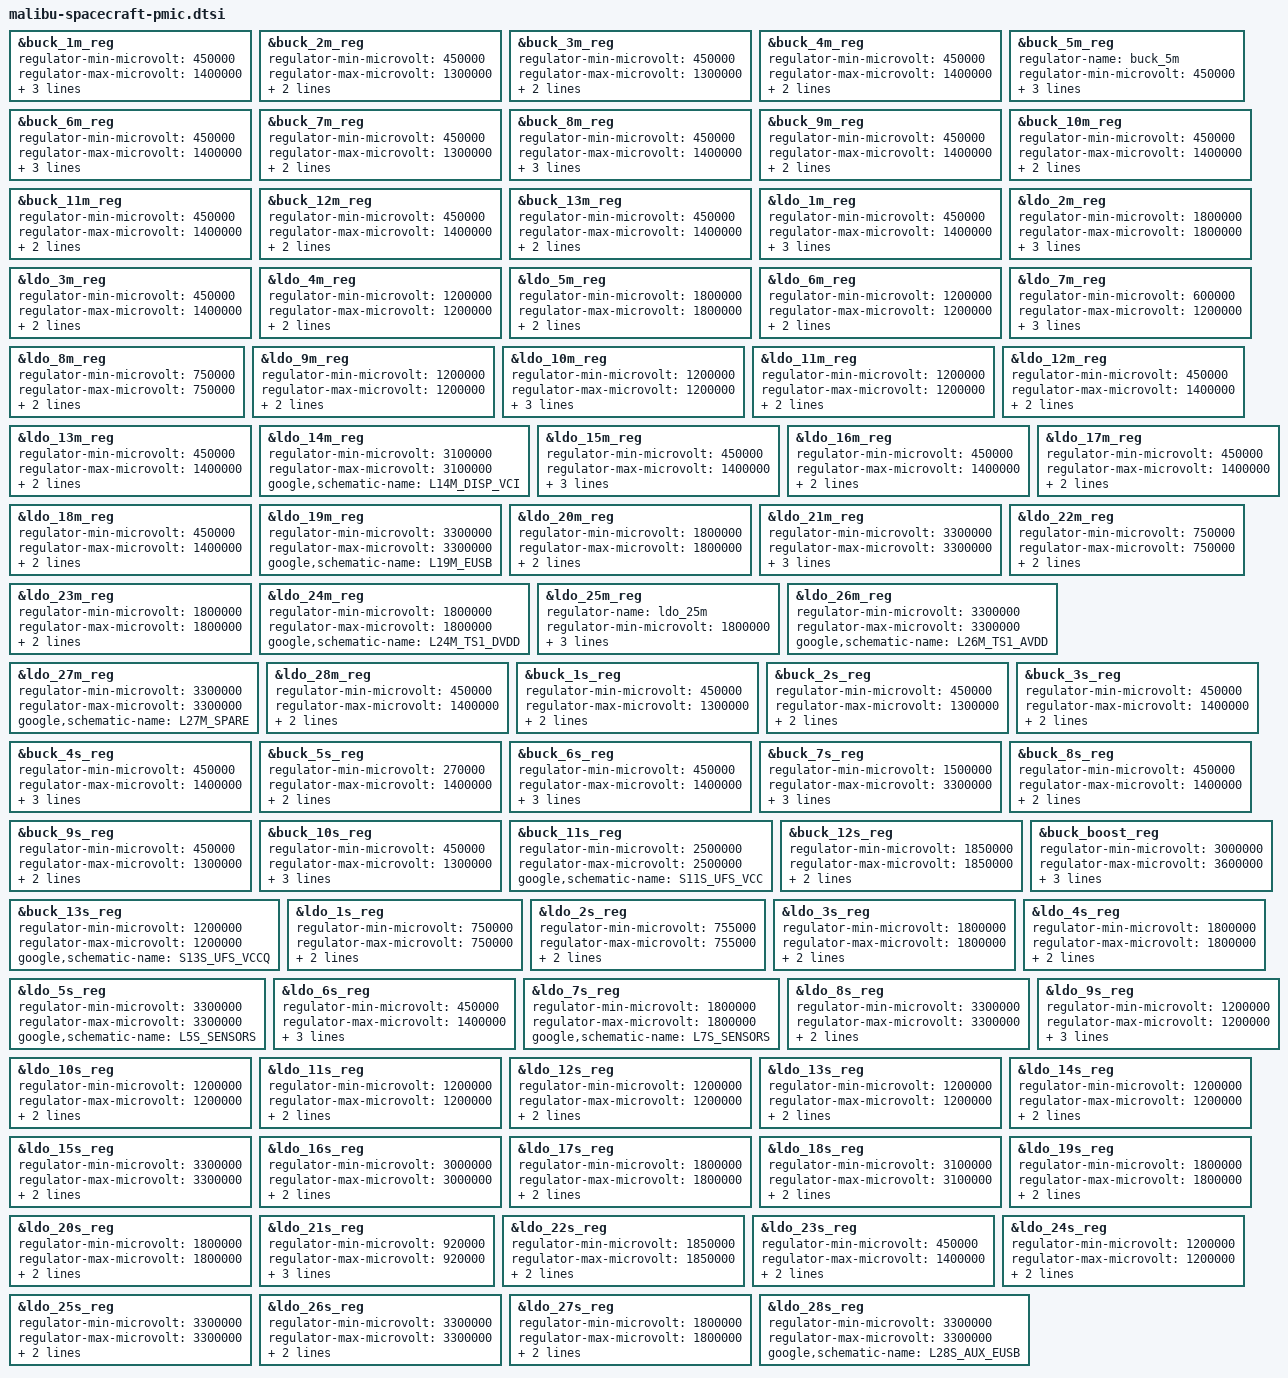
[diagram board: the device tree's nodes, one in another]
// SPDX-License-Identifier: GPL-2.0-only
/*
 * Spacecraft power regulator adjusment device tree source
 *
 * Copyright 2025 Google LLC
 */

&buck_1m_reg {
	regulator-min-microvolt = <450000>;
	regulator-max-microvolt = <1400000>;
	google,schematic-name = "S1M_VDD_AMB";
	google,subsystem-name = "AMB";
	google,monitor-only;
};

&buck_2m_reg {
	regulator-min-microvolt = <450000>;
	regulator-max-microvolt = <1300000>;
	google,schematic-name = "S2M_VDD_CPU2";
	google,monitor-only;
};

&buck_3m_reg {
	regulator-min-microvolt = <450000>;
	regulator-max-microvolt = <1300000>;
	google,schematic-name = "S3M_VDD_CPU1";
	google,monitor-only;
};

&buck_4m_reg {
	regulator-min-microvolt = <450000>;
	regulator-max-microvolt = <1400000>;
	google,schematic-name = "S4M_VDD_AUR";
	google,monitor-only;
};

&buck_5m_reg {
	regulator-name = "buck_5m";
	regulator-min-microvolt = <450000>;
	regulator-max-microvolt = <1300000>;
	google,schematic-name = "S5M_VDD_DSU";
	google,monitor-only;
};

&buck_6m_reg {
	regulator-min-microvolt = <450000>;
	regulator-max-microvolt = <1400000>;
	google,schematic-name = "S6M_LLDO1";
	google,monitor-only;
	regulator-always-on;
};

&buck_7m_reg {
	regulator-min-microvolt = <450000>;
	regulator-max-microvolt = <1300000>;
	google,schematic-name = "S7M_VDD_TPU";
	google,monitor-only;
};

&buck_8m_reg {
	regulator-min-microvolt = <450000>;
	regulator-max-microvolt = <1400000>;
	google,schematic-name = "S8M_LLDO2";
	google,monitor-only;
	regulator-always-on;
};

&buck_9m_reg {
	regulator-min-microvolt = <450000>;
	regulator-max-microvolt = <1400000>;
	google,schematic-name = "S9M_VDD_AOSS";
	google,monitor-only;
};

&buck_10m_reg {
	regulator-min-microvolt = <450000>;
	regulator-max-microvolt = <1400000>;
	google,schematic-name = "S10M_VDD_AOSS_OD";
	google,monitor-only;
};

&buck_11m_reg {
	regulator-min-microvolt = <450000>;
	regulator-max-microvolt = <1400000>;
	google,schematic-name = "S11M_VDD_DSU_M";
	google,monitor-only;
};

&buck_12m_reg {
	regulator-min-microvolt = <450000>;
	regulator-max-microvolt = <1400000>;
	google,schematic-name = "S12M_VDD_CPU1_M";
	google,monitor-only;
};

&buck_13m_reg {
	regulator-min-microvolt = <450000>;
	regulator-max-microvolt = <1400000>;
	google,schematic-name = "S13M_VDD_CPU0";
	google,monitor-only;
};

&ldo_1m_reg {
	regulator-min-microvolt = <450000>;
	regulator-max-microvolt = <1400000>;
	google,schematic-name = "L1M_ALIVE";
	google,monitor-only;
	regulator-always-on;
};

&ldo_2m_reg {
	regulator-min-microvolt = <1800000>;
	regulator-max-microvolt = <1800000>;
	google,schematic-name = "L2M_ALIVE";
	google,monitor-only;
	regulator-always-on;
};

&ldo_3m_reg {
	regulator-min-microvolt = <450000>;
	regulator-max-microvolt = <1400000>;
	google,schematic-name = "L3M_SPARE";
	google,monitor-only;
};

&ldo_4m_reg {
	regulator-min-microvolt = <1200000>;
	regulator-max-microvolt = <1200000>;
	google,schematic-name = "L4M_BT_AON";
	google,monitor-only;
};

&ldo_5m_reg {
	regulator-min-microvolt = <1800000>;
	regulator-max-microvolt = <1800000>;
	google,schematic-name = "L5M_S5910_AON";
	google,monitor-only;
};

&ldo_6m_reg {
	regulator-min-microvolt = <1200000>;
	regulator-max-microvolt = <1200000>;
	google,schematic-name = "L6M_HSI";
	google,monitor-only;
};

&ldo_7m_reg {
	/* Note:ldo_7m is current sink, not design to output voltage */
	regulator-min-microvolt = <600000>;
	regulator-max-microvolt = <1200000>;
	google,schematic-name = "L7M_SOC_GPIO";
	google,monitor-only;
	regulator-always-on;
};

&ldo_8m_reg {
	regulator-min-microvolt = <750000>;
	regulator-max-microvolt = <750000>;
	google,schematic-name = "L8M_SPARE";
	google,monitor-only;
};

&ldo_9m_reg {
	regulator-min-microvolt = <1200000>;
	regulator-max-microvolt = <1200000>;
	google,schematic-name = "L9M_SPARE";
	google,monitor-only;
};

&ldo_10m_reg {
	regulator-min-microvolt = <1200000>;
	regulator-max-microvolt = <1200000>;
	google,schematic-name = "L10M_SOC_GPIO";
	google,monitor-only;
	regulator-always-on;
};

&ldo_11m_reg {
	regulator-min-microvolt = <1200000>;
	regulator-max-microvolt = <1200000>;
	google,schematic-name = "L11M_VDD_CPU0_M";
	google,monitor-only;
};

&ldo_12m_reg {
	regulator-min-microvolt = <450000>;
	regulator-max-microvolt = <1400000>;
	google,schematic-name = "L12M_VDD_CPU2_M";
	google,monitor-only;
};

&ldo_13m_reg {
	regulator-min-microvolt = <450000>;
	regulator-max-microvolt = <1400000>;
	google,schematic-name = "L13M_VDD_TPU_M";
	google,monitor-only;
};

&ldo_14m_reg {
	regulator-min-microvolt = <3100000>;
	regulator-max-microvolt = <3100000>;
	google,schematic-name = "L14M_DISP_VCI";
};

&ldo_15m_reg {
	regulator-min-microvolt = <450000>;
	regulator-max-microvolt = <1400000>;
	google,schematic-name = "L15M_USB_PCIE";
	google,monitor-only;
	regulator-always-on;
};

&ldo_16m_reg {
	regulator-min-microvolt = <450000>;
	regulator-max-microvolt = <1400000>;
	google,schematic-name = "L16M_VDD_AMB_M";
	google,monitor-only;
};

&ldo_17m_reg {
	regulator-min-microvolt = <450000>;
	regulator-max-microvolt = <1400000>;
	google,schematic-name = "L17M_VDD_TPU_SSWRP";
	google,monitor-only;
};

&ldo_18m_reg {
	regulator-min-microvolt = <450000>;
	regulator-max-microvolt = <1400000>;
	google,schematic-name = "L18M_SPARE";
	google,monitor-only;
};

&ldo_19m_reg {
	regulator-min-microvolt = <3300000>;
	regulator-max-microvolt = <3300000>;
	google,schematic-name = "L19M_EUSB";
};

&ldo_20m_reg {
	regulator-min-microvolt = <1800000>;
	regulator-max-microvolt = <1800000>;
	google,schematic-name = "L20M_DMIC1";
	google,monitor-only;
};

&ldo_21m_reg {
	regulator-min-microvolt = <3300000>;
	regulator-max-microvolt = <3300000>;
	google,schematic-name = "L21M_GSC";
	google,monitor-only;
	regulator-always-on;
};

&ldo_22m_reg {
	regulator-min-microvolt = <750000>;
	regulator-max-microvolt = <750000>;
	google,schematic-name = "L22M_SPARE";
	google,monitor-only;
};

&ldo_23m_reg {
	regulator-min-microvolt = <1800000>;
	regulator-max-microvolt = <1800000>;
	google,schematic-name = "L23M_SPARE";
	google,monitor-only;
};

&ldo_24m_reg {
	regulator-min-microvolt = <1800000>;
	regulator-max-microvolt = <1800000>;
	google,schematic-name = "L24M_TS1_DVDD";
};

&ldo_25m_reg {
	regulator-name = "ldo_25m";
	regulator-min-microvolt = <1800000>;
	regulator-max-microvolt = <1800000>;
	google,schematic-name = "L25M_AVDD_OTP";
	google,monitor-only;
};

&ldo_26m_reg {
	regulator-min-microvolt = <3300000>;
	regulator-max-microvolt = <3300000>;
	google,schematic-name = "L26M_TS1_AVDD";
};

&ldo_27m_reg {
	regulator-min-microvolt = <3300000>;
	regulator-max-microvolt = <3300000>;
	google,schematic-name = "L27M_SPARE";
};

&ldo_28m_reg {
	regulator-min-microvolt = <450000>;
	regulator-max-microvolt = <1400000>;
	google,schematic-name = "L28M_VDD_HSION";
	google,monitor-only;
};

&buck_1s_reg {
	regulator-min-microvolt = <450000>;
	regulator-max-microvolt = <1300000>;
	google,schematic-name = "S1S_VDD_MM";
	google,monitor-only;
};

&buck_2s_reg {
	regulator-min-microvolt = <450000>;
	regulator-max-microvolt = <1300000>;
	google,schematic-name = "S2S_VDD_GPU";
	google,monitor-only;
};

&buck_3s_reg {
	regulator-min-microvolt = <450000>;
	regulator-max-microvolt = <1400000>;
	google,schematic-name = "S3S_LLDO1";
	google,monitor-only;
};

&buck_4s_reg {
	regulator-min-microvolt = <450000>;
	regulator-max-microvolt = <1400000>;
	google,schematic-name = "S4S_VDD2H_MEM";
	google,monitor-only;
	regulator-always-on;
};

&buck_5s_reg {
	regulator-min-microvolt = <270000>;
	regulator-max-microvolt = <1400000>;
	google,schematic-name = "S5S_VDDQ_MEM";
	google,monitor-only;
};

&buck_6s_reg {
	regulator-min-microvolt = <450000>;
	regulator-max-microvolt = <1400000>;
	google,schematic-name = "S6S_LLDO2";
	google,monitor-only;
	regulator-always-on;
};

&buck_7s_reg {
	regulator-min-microvolt = <1500000>;
	regulator-max-microvolt = <3300000>;
	google,schematic-name = "S7S_MLDO";
	google,monitor-only;
	regulator-always-on;
};

&buck_8s_reg {
	regulator-min-microvolt = <450000>;
	regulator-max-microvolt = <1400000>;
	google,schematic-name = "S8S_VDD_GMC";
	google,monitor-only;
};

&buck_9s_reg {
	regulator-min-microvolt = <450000>;
	regulator-max-microvolt = <1300000>;
	google,schematic-name = "S9S_VDD_INFRA";
	google,monitor-only;
};

&buck_10s_reg {
	regulator-min-microvolt = <450000>;
	regulator-max-microvolt = <1300000>;
	google,schematic-name = "S10S_VDD_INFRA_MM_GPU_AUR_M";
	google,monitor-only;
};

&buck_11s_reg {
	regulator-min-microvolt = <2500000>;
	regulator-max-microvolt = <2500000>;
	google,schematic-name = "S11S_UFS_VCC";
};

&buck_12s_reg {
	regulator-min-microvolt = <1850000>;
	regulator-max-microvolt = <1850000>;
	google,schematic-name = "S12S";
	regulator-always-on;
};

&buck_13s_reg {
	regulator-min-microvolt = <1200000>;
	regulator-max-microvolt = <1200000>;
	google,schematic-name = "S13S_UFS_VCCQ";
};

&buck_boost_reg {
	regulator-min-microvolt = <3000000>;
	regulator-max-microvolt = <3600000>;
	google,schematic-name = "BB_HLDO";
	google,monitor-only;
	regulator-always-on;
};

&ldo_1s_reg {
	regulator-min-microvolt = <750000>;
	regulator-max-microvolt = <750000>;
	google,schematic-name = "L1S_PLL_HSIO";
	regulator-always-on;
};

&ldo_2s_reg {
	regulator-min-microvolt = <755000>;
	regulator-max-microvolt = <755000>;
	google,schematic-name = "L2S_CSI";
	google,monitor-only;
};

&ldo_3s_reg {
	regulator-min-microvolt = <1800000>;
	regulator-max-microvolt = <1800000>;
	google,schematic-name = "L3S";
	regulator-always-on;
};

&ldo_4s_reg {
	regulator-min-microvolt = <1800000>;
	regulator-max-microvolt = <1800000>;
	google,schematic-name = "L4S_SPARE";
	google,monitor-only;
};

&ldo_5s_reg {
	regulator-min-microvolt = <3300000>;
	regulator-max-microvolt = <3300000>;
	google,schematic-name = "L5S_SENSORS";
};

&ldo_6s_reg {
	regulator-min-microvolt = <450000>;
	regulator-max-microvolt = <1400000>;
	google,schematic-name = "L6S_VDD_GMC_M";
	google,monitor-only;
	regulator-always-on;
};

&ldo_7s_reg {
	regulator-min-microvolt = <1800000>;
	regulator-max-microvolt = <1800000>;
	google,schematic-name = "L7S_SENSORS";
};

&ldo_8s_reg {
	regulator-min-microvolt = <3300000>;
	regulator-max-microvolt = <3300000>;
	google,schematic-name = "L8S_LDAF";
	google,monitor-only;
};

&ldo_9s_reg {
	regulator-min-microvolt = <1200000>;
	regulator-max-microvolt = <1200000>;
	google,schematic-name = "L9S_GNSS_CORE";
	regulator-allow-bypass;
	google,monitor-only;
};

&ldo_10s_reg {
	regulator-min-microvolt = <1200000>;
	regulator-max-microvolt = <1200000>;
	google,schematic-name = "L10S_SENSORS";
	google,monitor-only;
};

&ldo_11s_reg {
	regulator-min-microvolt = <1200000>;
	regulator-max-microvolt = <1200000>;
	google,schematic-name = "L11S_AMP";
	google,monitor-only;
};

&ldo_12s_reg {
	regulator-min-microvolt = <1200000>;
	regulator-max-microvolt = <1200000>;
	google,schematic-name = "L12S_NFC";
	regulator-always-on;
};

&ldo_13s_reg {
	regulator-min-microvolt = <1200000>;
	regulator-max-microvolt = <1200000>;
	google,schematic-name = "L13S_SPARE";
	google,monitor-only;
};

&ldo_14s_reg {
	regulator-min-microvolt = <1200000>;
	regulator-max-microvolt = <1200000>;
	google,schematic-name = "L14S_SPARE";
	google,monitor-only;
};

&ldo_15s_reg {
	regulator-min-microvolt = <3300000>;
	regulator-max-microvolt = <3300000>;
	google,schematic-name = "L15S_SPARE";
	google,monitor-only;
};

&ldo_16s_reg {
	regulator-min-microvolt = <3000000>;
	regulator-max-microvolt = <3000000>;
	google,schematic-name = "L16S_UWB";
	google,monitor-only;
};

&ldo_17s_reg {
	regulator-min-microvolt = <1800000>;
	regulator-max-microvolt = <1800000>;
	google,schematic-name = "L17S_UWB";
	google,monitor-only;
};

&ldo_18s_reg {
	regulator-min-microvolt = <3100000>;
	regulator-max-microvolt = <3100000>;
	google,schematic-name = "L18S";
	google,monitor-only;
};

&ldo_19s_reg {
	regulator-min-microvolt = <1800000>;
	regulator-max-microvolt = <1800000>;
	google,schematic-name = "L19S_DMIC3";
	google,monitor-only;
};

&ldo_20s_reg {
	regulator-min-microvolt = <1800000>;
	regulator-max-microvolt = <1800000>;
	google,schematic-name = "L20S_DMIC2";
	google,monitor-only;
};

&ldo_21s_reg {
	regulator-min-microvolt = <920000>;
	regulator-max-microvolt = <920000>;
	google,schematic-name = "L21S_VDD2L_MEM";
	google,monitor-only;
	regulator-always-on;
};

&ldo_22s_reg {
	regulator-min-microvolt = <1850000>;
	regulator-max-microvolt = <1850000>;
	google,schematic-name = "L22S_CAMIO";

	/* b/418913720 - go/regulator-circular-dep */
	/* Workaround to avoid I2C issue when controller resume and suspend
	   outside of camera usage. */
	regulator-always-on;
};

&ldo_23s_reg {
	regulator-min-microvolt = <450000>;
	regulator-max-microvolt = <1400000>;
	google,schematic-name = "L23S_SPARE";
	google,monitor-only;
};

&ldo_24s_reg {
	regulator-min-microvolt = <1200000>;
	regulator-max-microvolt = <1200000>;
	google,schematic-name = "L24S_HSI";
	regulator-always-on;
};

&ldo_25s_reg {
	regulator-min-microvolt = <3300000>;
	regulator-max-microvolt = <3300000>;
	google,schematic-name = "L25S_SPARE";
	regulator-always-on;
};

&ldo_26s_reg {
	regulator-min-microvolt = <3300000>;
	regulator-max-microvolt = <3300000>;
	google,schematic-name = "L26S";
	google,monitor-only;
};

&ldo_27s_reg {
	regulator-min-microvolt = <1800000>;
	regulator-max-microvolt = <1800000>;
	google,schematic-name = "L27S";
	google,monitor-only;
};

&ldo_28s_reg {
	regulator-min-microvolt = <3300000>;
	regulator-max-microvolt = <3300000>;
	google,schematic-name = "L28S_AUX_EUSB";
};
